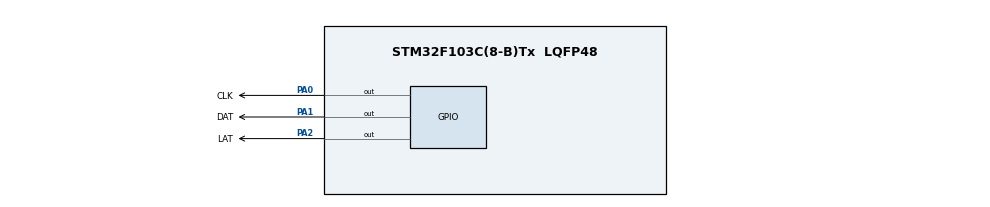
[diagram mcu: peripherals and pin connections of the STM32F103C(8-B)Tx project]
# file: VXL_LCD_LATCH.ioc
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Mcu.Family=STM32F1
Mcu.Name=STM32F103C(8-B)Tx
Mcu.Package=LQFP48
NVIC.PriorityGroup=NVIC_PRIORITYGROUP_4
PA0-WKUP.GPIO_Label=CLK
PA0-WKUP.Signal=GPIO_Output
PA1.GPIO_Label=DAT
PA1.Signal=GPIO_Output
PA13.Mode=Serial_Wire
PA13.Signal=SYS_JTMS-SWDIO
PA14.Mode=Serial_Wire
PA14.Signal=SYS_JTCK-SWCLK
PA2.GPIO_Label=LAT
PA2.Signal=GPIO_Output
ProjectManager.HeapSize=0x200
ProjectManager.StackSize=0x400
ProjectManager.TargetToolchain=MDK-ARM V5.32
RCC.APB1Freq_Value=8000000
RCC.APB2Freq_Value=8000000
board=custom

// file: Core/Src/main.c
/* USER CODE BEGIN Header */
/**
  ******************************************************************************
  * @file           : main.c
  * @brief          : Main program body
  ******************************************************************************
  * @attention
  *
  * Copyright (c) 2023 STMicroelectronics.
  * All rights reserved.
  *
  * This software is licensed under terms that can be found in the LICENSE file
  * in the root directory of this software component.
  * If no LICENSE file comes with this software, it is provided AS-IS.
  *
  ******************************************************************************
  */
/* USER CODE END Header */
#include "main.h"

/* USER CODE BEGIN Includes */
#include "chi_LCD_WithShiftRegister.h"
/* USER CODE END Includes */

void SystemClock_Config(void);
static void MX_GPIO_Init(void);

int main(void)
{

  /* MCU Configuration--------------------------------------------------------*/

  /* Reset of all peripherals, Initializes the Flash interface and the Systick. */
  HAL_Init();

  /* Configure the system clock */
  SystemClock_Config();

  /* Initialize all configured peripherals */
  MX_GPIO_Init();
  /* USER CODE BEGIN 2 */
	HAL_GPIO_WritePin(CLK_GPIO_Port,CLK_Pin,0);
	HAL_GPIO_WritePin(LAT_GPIO_Port,LAT_Pin,0);

	LCD_init();

	LCD_gotoXY(1,0);
	LCD_printf((uint8_t *)"NGUYEN HUU CHI");

	LCD_gotoXY(3,1);
	LCD_printf((uint8_t *)" 20146479 ");
  /* USER CODE END 2 */

  /* Infinite loop */
  while (1)
  {

  }
}

void SystemClock_Config(void)
{
  RCC_OscInitTypeDef RCC_OscInitStruct = {0};
  RCC_ClkInitTypeDef RCC_ClkInitStruct = {0};

  /** Initializes the RCC Oscillators according to the specified parameters
  * in the RCC_OscInitTypeDef structure.
  */
  RCC_OscInitStruct.OscillatorType = RCC_OSCILLATORTYPE_HSI;
  RCC_OscInitStruct.HSIState = RCC_HSI_ON;
  RCC_OscInitStruct.HSICalibrationValue = RCC_HSICALIBRATION_DEFAULT;
  RCC_OscInitStruct.PLL.PLLState = RCC_PLL_NONE;
  if (HAL_RCC_OscConfig(&RCC_OscInitStruct) != HAL_OK)
  {
    Error_Handler();
  }

  /** Initializes the CPU, AHB and APB buses clocks
  */
  RCC_ClkInitStruct.ClockType = RCC_CLOCKTYPE_HCLK|RCC_CLOCKTYPE_SYSCLK
                              |RCC_CLOCKTYPE_PCLK1|RCC_CLOCKTYPE_PCLK2;
  RCC_ClkInitStruct.SYSCLKSource = RCC_SYSCLKSOURCE_HSI;
  RCC_ClkInitStruct.AHBCLKDivider = RCC_SYSCLK_DIV1;
  RCC_ClkInitStruct.APB1CLKDivider = RCC_HCLK_DIV1;
  RCC_ClkInitStruct.APB2CLKDivider = RCC_HCLK_DIV1;

  if (HAL_RCC_ClockConfig(&RCC_ClkInitStruct, FLASH_LATENCY_0) != HAL_OK)
  {
    Error_Handler();
  }
}

static void MX_GPIO_Init(void)
{
  GPIO_InitTypeDef GPIO_InitStruct = {0};

  /* GPIO Ports Clock Enable */
  __HAL_RCC_GPIOC_CLK_ENABLE();
  __HAL_RCC_GPIOD_CLK_ENABLE();
  __HAL_RCC_GPIOA_CLK_ENABLE();
  __HAL_RCC_GPIOB_CLK_ENABLE();

  /*Configure GPIO pin Output Level */
  HAL_GPIO_WritePin(GPIOA, CLK_Pin|DAT_Pin|LAT_Pin, GPIO_PIN_RESET);

  /*Configure GPIO pins : PC13 PC14 PC15 */
  GPIO_InitStruct.Pin = GPIO_PIN_13|GPIO_PIN_14|GPIO_PIN_15;
  GPIO_InitStruct.Mode = GPIO_MODE_ANALOG;
  HAL_GPIO_Init(GPIOC, &GPIO_InitStruct);

  /*Configure GPIO pins : PD0 PD1 */
  GPIO_InitStruct.Pin = GPIO_PIN_0|GPIO_PIN_1;
  GPIO_InitStruct.Mode = GPIO_MODE_ANALOG;
  HAL_GPIO_Init(GPIOD, &GPIO_InitStruct);

  /*Configure GPIO pins : CLK_Pin DAT_Pin LAT_Pin */
  GPIO_InitStruct.Pin = CLK_Pin|DAT_Pin|LAT_Pin;
  GPIO_InitStruct.Mode = GPIO_MODE_OUTPUT_PP;
  GPIO_InitStruct.Pull = GPIO_NOPULL;
  GPIO_InitStruct.Speed = GPIO_SPEED_FREQ_LOW;
  HAL_GPIO_Init(GPIOA, &GPIO_InitStruct);

  /*Configure GPIO pins : PA3 PA4 PA5 PA6
                           PA7 PA8 PA9 PA10
                           PA11 PA12 PA15 */
  GPIO_InitStruct.Pin = GPIO_PIN_3|GPIO_PIN_4|GPIO_PIN_5|GPIO_PIN_6
                          |GPIO_PIN_7|GPIO_PIN_8|GPIO_PIN_9|GPIO_PIN_10
                          |GPIO_PIN_11|GPIO_PIN_12|GPIO_PIN_15;
  GPIO_InitStruct.Mode = GPIO_MODE_ANALOG;
  HAL_GPIO_Init(GPIOA, &GPIO_InitStruct);

  /*Configure GPIO pins : PB0 PB1 PB2 PB10
                           PB11 PB12 PB13 PB14
                           PB15 PB3 PB4 PB5
                           PB6 PB7 PB8 PB9 */
  GPIO_InitStruct.Pin = GPIO_PIN_0|GPIO_PIN_1|GPIO_PIN_2|GPIO_PIN_10
                          |GPIO_PIN_11|GPIO_PIN_12|GPIO_PIN_13|GPIO_PIN_14
                          |GPIO_PIN_15|GPIO_PIN_3|GPIO_PIN_4|GPIO_PIN_5
                          |GPIO_PIN_6|GPIO_PIN_7|GPIO_PIN_8|GPIO_PIN_9;
  GPIO_InitStruct.Mode = GPIO_MODE_ANALOG;
  HAL_GPIO_Init(GPIOB, &GPIO_InitStruct);

  /*Configure peripheral I/O remapping */
  __HAL_AFIO_REMAP_PD01_ENABLE();

}

void Error_Handler(void)
{
  __disable_irq();
  while (1)
  {
  }
}
